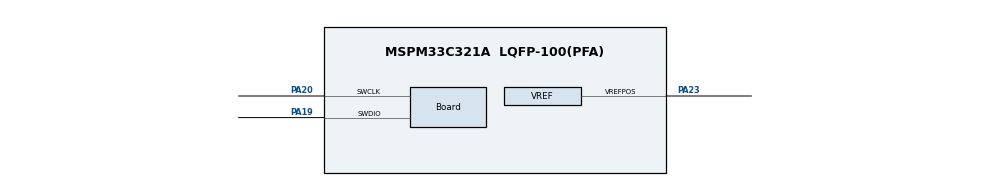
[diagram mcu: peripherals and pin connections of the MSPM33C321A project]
//@cliArgs --device "MSPM33C321A" --package "LQFP-100(PFA)" --part "Default"
//@v2CliArgs --device "MSPM33C321A" --package "LQFP-100(PFA)"
// @cliArgs --board /ti/boards/LP_MSPM33C321A --rtos nortos

/**
 * Import the modules used in this configuration.
 */
const Board  = scripting.addModule("/ti/driverlib/Board");
const HSADC  = scripting.addModule("/ti/driverlib/HSADC", {}, false);
const HSADC1 = HSADC.addInstance();
const SYSCTL = scripting.addModule("/ti/driverlib/SYSCTL");
const VREF   = scripting.addModule("/ti/driverlib/VREF");

/**
 * Write custom configuration values to the imported modules.
 */
Board.peripheral.$assign          = "DEBUGSS";
Board.peripheral.swclkPin.$assign = "PA20";
Board.peripheral.swdioPin.$assign = "PA19";

HSADC1.$name                      = "HSADC0";
HSADC1.enabledSOCs                = ["ADC_SOC_NUMBER0"];
HSADC1.soc0enableComparator       = true;
HSADC1.enabledSEQs                = ["ADC_SEQ_NUMBER1"];
HSADC1.seq1Enable                 = true;
HSADC1.seq1SampleWindow           = 16;
HSADC1.enabledInts                = ["ADC_INT_NUMBER_1"];
HSADC1.enableInterrupt1           = true;
HSADC1.adcEventInterrupt          = true;
HSADC1.enabledPPBs                = ["ADC_PPB_NUMBER1"];
HSADC1.ppb1EventEnable            = ["ADC_EVT_TRIPLO"];
HSADC1.ppb1EventInterruptEnable   = ["ADC_EVT_TRIPLO"];
HSADC1.ppb1LowTripLimit           = 15;
HSADC1.peripheral.$assign         = "ADC0";
HSADC1.peripheral.adcPin0.$assign = "PA27";

SYSCTL.forceDefaultClkConfig = true;
SYSCTL.peripheral.$assign    = "SYSCTL";

VREF.peripheral.$assign            = "VREF";
VREF.peripheral.vrefPosPin.$assign = "PA23";
VREF.vrefPosPinConfig.$name        = "ti_driverlib_gpio_GPIOPinGeneric0";

const ProjectConfig              = scripting.addModule("/ti/project_config/ProjectConfig", {}, false);
ProjectConfig.migrationCondition = true;
